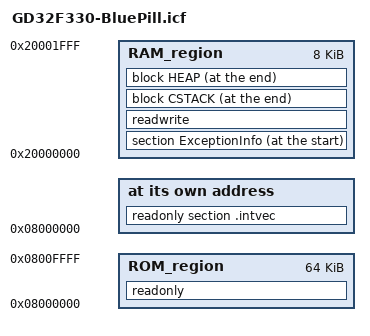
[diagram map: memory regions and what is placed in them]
/*###ICF### Section handled by ICF editor, don't touch! ****/
/*-Editor annotation file-*/
/* IcfEditorFile="$TOOLKIT_DIR$\config\ide\IcfEditor\cortex_v1_0.xml" */
/*-Specials-*/
define symbol __ICFEDIT_intvec_start__ = 0x08000000;
/*-Memory Regions-*/
define symbol __ICFEDIT_region_ROM_start__ = 0x08000000;
define symbol __ICFEDIT_region_ROM_end__   = 0x0800FFFF;
define symbol __ICFEDIT_region_RAM_start__ = 0x20000000;
define symbol __ICFEDIT_region_RAM_end__   = 0x20001FFF;
/*-Sizes-*/
define symbol __ICFEDIT_size_cstack__ = 0x400;
define symbol __ICFEDIT_size_heap__   = 0x200;
define symbol __ICF_region_ROM_size   = __ICFEDIT_region_ROM_end__ + 1 - __ICFEDIT_region_ROM_start__;
/**** End of ICF editor section. ###ICF###*/

/* Export the above symbols so they can be seen by the application program */
/* See "Interaction between the tools and your application" in EWARM_DevelopmentGuide.ENU.pdf */
/* The header file ICF_Symbols.h contains C declaration for them. */
export symbol __ICFEDIT_intvec_start__;
export symbol __ICFEDIT_region_ROM_start__;
export symbol __ICFEDIT_region_ROM_end__;
export symbol __ICFEDIT_region_RAM_start__;
export symbol __ICFEDIT_region_RAM_end__;
export symbol __ICFEDIT_size_cstack__;
export symbol __ICFEDIT_size_heap__;
export symbol __ICF_region_ROM_size;

define memory mem with size = 4G;
define region ROM_region    = mem:[from __ICFEDIT_region_ROM_start__ to __ICFEDIT_region_ROM_end__];
define region RAM_region    = mem:[from __ICFEDIT_region_RAM_start__ to __ICFEDIT_region_RAM_end__];

define block CSTACK    with alignment = 8, size = __ICFEDIT_size_cstack__   { };
define block HEAP      with alignment = 8, size = __ICFEDIT_size_heap__     { };

initialize by copy { readwrite };
do not initialize  { section .noinit, section ExceptionInfo };

place at address mem:__ICFEDIT_intvec_start__ { readonly section .intvec };
place in ROM_region { readonly };
place at start of RAM_region {section ExceptionInfo};
place in RAM_region { readwrite }; 
place at end of RAM_region { block CSTACK, block HEAP };
